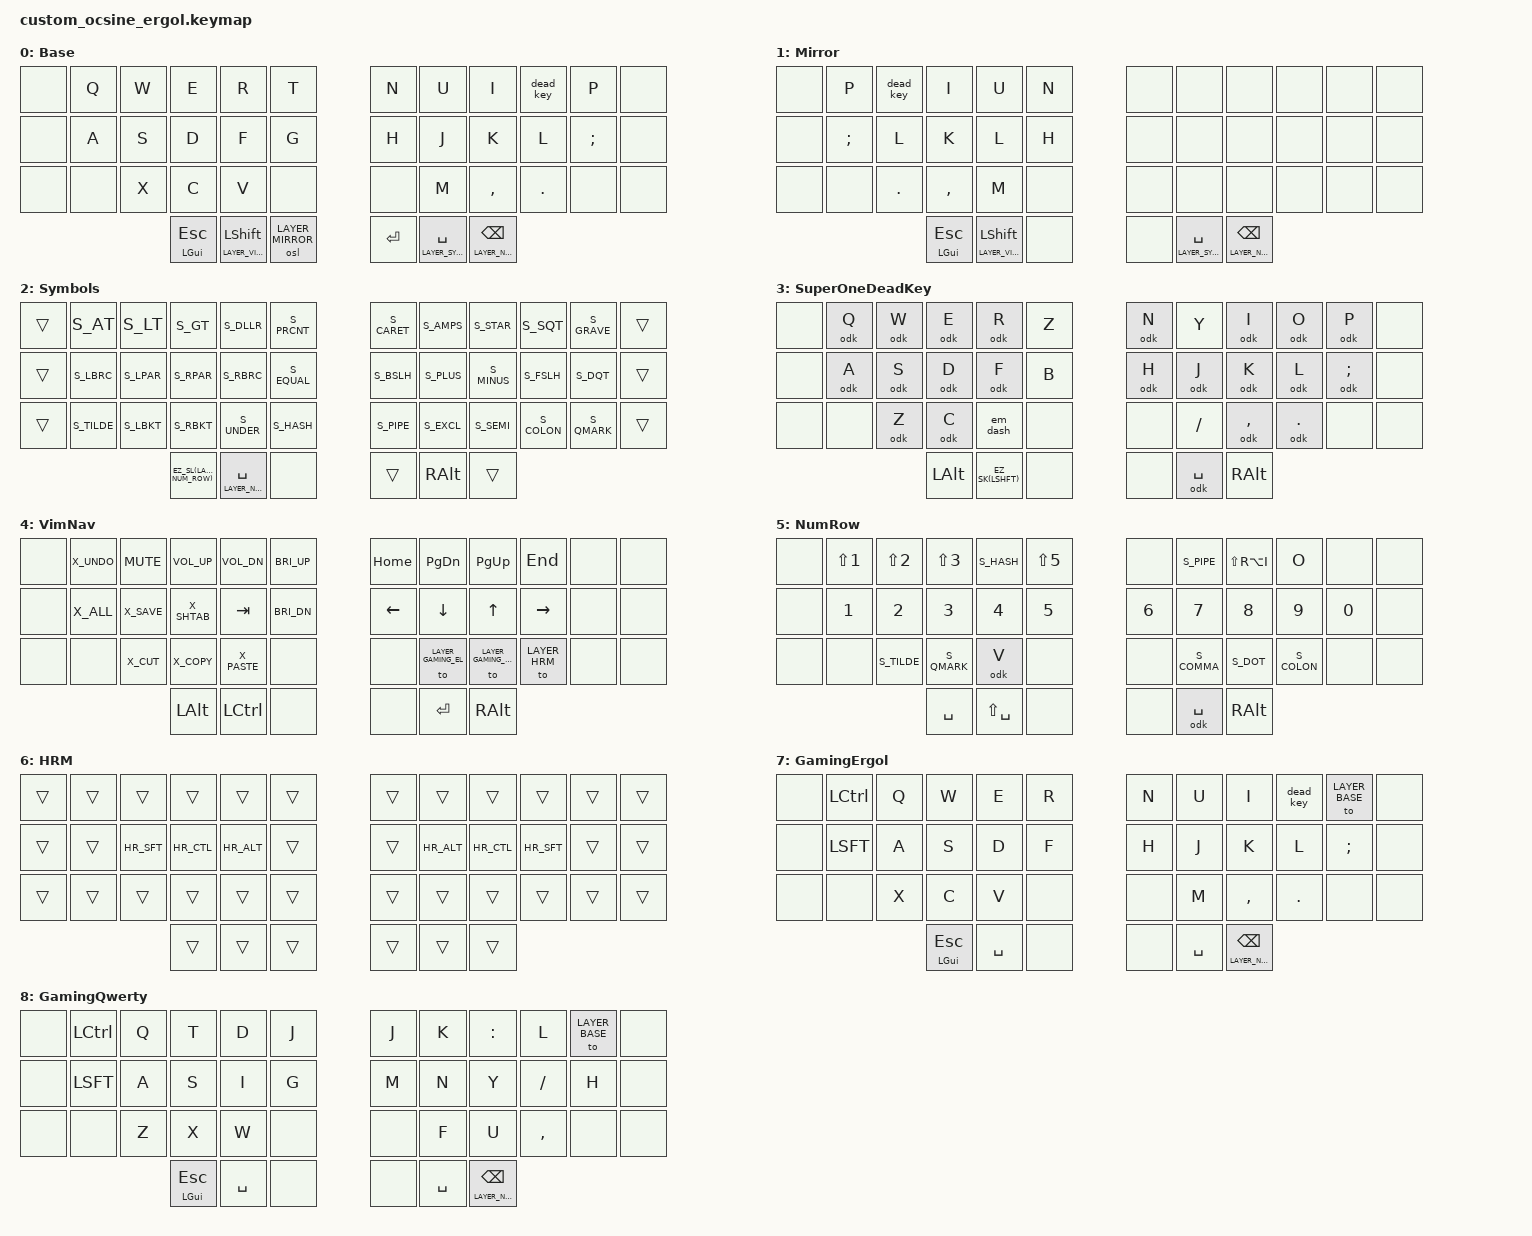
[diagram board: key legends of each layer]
#include <behaviors.dtsi>
#include <dt-bindings/zmk/keys.h>

#define TAPPING_TERM 175
#include "hold_taps.dtsi"

#define KB_LAYOUT_ERGOL
#include "aliases.h"

/* &caps_word { */
/*   no-default-keys; */
/*   continue-list = <C O N DOT BACKSPACE>; */
/*   shift-list = < */
/*     Q  W  E  R  T     Y  U  I     P */
/*     A  S  D  F  G     H  J  K  L  SEMI */
/*     Z  X     V  B        M  COMMA FSLH */
/*   >; */
/* }; */

#undef  HRM_S
#undef  HRM_L
#define HRM_S   &hrm LSFT S
#define HRM_L   &hrm LSFT L

&hrm { tapping-term-ms = <250>; };
#define COMBO_TIMEOUT_MS 17
#define COMBO_LOCK_MS 125

#define LAYER_BASE      0
#define LAYER_MIRROR    1
#define LAYER_SYMBOLS   2
#define LAYER_ODK       3
#define LAYER_VIM_NAV   4
#define LAYER_NUM_ROW   5
#define LAYER_HRM       6
#define LAYER_GAMING_EL 7
#define LAYER_GAMING_QW 8

#define S_MULT &kp LS(RA(I))

#define X_BASE    &to LAYER_BASE
#define X_HRM     &to LAYER_HRM
#define X_GAME_EL &to LAYER_GAMING_EL
#define X_GAME_QW &to LAYER_GAMING_QW

#define X_MUTE  &kp C_MUTE
#define X_VOLUP &kp C_VOL_UP
#define X_VOLDN &kp C_VOL_DN
#define X_BRIUP &kp C_BRI_UP
#define X_BRIDN &kp C_BRI_DN

/ {
  behaviors {
    hrt: hom_row_mods_transparent {
      compatible = "zmk,behavior-hold-tap";
      #binding-cells = <2>;
      tapping-term-ms = <250>;
      quick-tap-ms = <QUICK_TAP>;
      flavor = "tap-preferred";
      bindings = <&kp>, <&trans>;
    };

    ltsk: layer_tap_sticky_key {
      compatible = "zmk,behavior-hold-tap";
      #binding-cells = <2>;
      tapping-term-ms = <TAPPING_TERM>;
      flavor = "tap-preferred";
      bindings = <&mo>, <&osm>;
    };

    dead_key: dead_key {
      compatible = "zmk,behavior-mod-morph";
      #binding-cells = <0>;
      bindings = <&bsl LAYER_ODK LAYER_ODK>, <&kp O>;
      mods = <(MOD_LSFT|MOD_RSFT|MOD_RALT|MOD_LGUI)>;
      keep-mods = <(MOD_LSFT|MOD_RSFT|MOD_RALT|MOD_LGUI|MOD_LCTL)>;
    };

    /* // Macro to tap Ergo‑L’s ODK before the specified key */
    /* odk: one_dead_key_macro { */
    /*   compatible = "zmk,behavior-dead-key"; */
    /*   #binding-cells = <1>; */
    /*   dead-keycode = <O>; */
    /* }; */

    // Macro to tap Ergo‑L’s ODK before the specified key
    odk: one_dead_key_macro {
      compatible = "zmk,behavior-macro-one-param";
      #binding-cells = <1>;
      tap-ms = <0>;
      wait-ms = <0>;
      bindings
        = <&macro_tap &kp O>
        , <&macro_param_1to1>
        , <&macro_tap &kp MACRO_PLACEHOLDER>
        ;
    };

    em_dash: em_dash {
      compatible = "zmk,behavior-mod-morph";
      #binding-cells = <0>;
      bindings = <&odk V>, <&odk B>;
      mods = <(MOD_LSFT|MOD_RSFT)>;
    };

    /* macro_plus_to_zero: macro_plus_to_zero { */
    /*   compatible = "zmk,behavior-macro"; */
    /*   #binding-cells = <0>; */
    /*   tap-ms = <0>; */
    /*   wait-ms = <0>; */
    /*   bindings */
    /*     = <&macro_tap &kp BACKSPACE> */
    /*     , <&macro_tap &kp N0> */
    /*     ; */
    /* }; */
    /**/
    /* plus: magic_plus { */
    /*   compatible = "zmk,behavior-flow-key"; */
    /*   #binding-cells = <0>; */
    /*   timeout-ms = <QUICK_TAP>; */
    /*   bindings */
    /*     = <S_PLUS> */
    /*     , <S_MINUS &macro_plus_to_zero> */
    /*     ; */
    /* }; */
    /**/
    /* macro_minus_to_one: macro_minus_to_one { */
    /*   compatible = "zmk,behavior-macro"; */
    /*   #binding-cells = <0>; */
    /*   tap-ms = <0>; */
    /*   wait-ms = <0>; */
    /*   bindings */
    /*     = <&macro_tap &kp BACKSPACE> */
    /*     , <&macro_tap &kp N1> */
    /*     ; */
    /* }; */
    /**/
    /* minus: magic_minus { */
    /*   compatible = "zmk,behavior-flow-key"; */
    /*   #binding-cells = <0>; */
    /*   timeout-ms = <QUICK_TAP>; */
    /*   bindings */
    /*     = <S_MINUS> */
    /*     , <S_PLUS &macro_minus_to_one> */
    /*     ; */
    /* }; */
    /**/
    /* macro_slash_to_minus_one: macro_slash_to_minus_one { */
    /*   compatible = "zmk,behavior-macro"; */
    /*   #binding-cells = <0>; */
    /*   tap-ms = <0>; */
    /*   wait-ms = <0>; */
    /*   bindings */
    /*     = <&macro_tap &kp BACKSPACE> */
    /*     , <&macro_tap S_MINUS> */
    /*     , <&macro_tap &kp N1> */
    /*     ; */
    /* }; */
    /**/
    /* slash: magic_slash { */
    /*   compatible = "zmk,behavior-flow-key"; */
    /*   #binding-cells = <0>; */
    /*   timeout-ms = <QUICK_TAP>; */
    /*   bindings */
    /*     = <S_FSLH> */
    /*     , <S_PLUS &macro_slash_to_minus_one> */
    /*     ; */
    /* }; */
  };

  combos {
    compatible= "zmk,combos";

    #define HOME_ROW 12
    #define BOT_ROW  24

    #define LRING   2
    #define LMIDDLE 3
    #define LINDEX  4
    #define RINDEX  7
    #define RMIDDLE 8
    #define RRING   9

    compose_sd {
      key-positions = <(HOME_ROW + LRING) (HOME_ROW + LMIDDLE)>;
      bindings = <&kp NUBS>;
      timeout-ms = <COMBO_TIMEOUT_MS>;
      require-prior-idle-ms = <COMBO_LOCK_MS>;
      layers = <LAYER_BASE>;
    };

    /* enter_df { */
    /*   key-positions = <(HOME_ROW + LMIDDLE) (HOME_ROW + LINDEX)>; */
    /*   bindings = <&kp ENTER>; */
    /*   timeout-ms = <COMBO_TIMEOUT_MS>; */
    /*   require-prior-idle-ms = <COMBO_LOCK_MS>; */
    /*   layers = <LAYER_BASE>; */
    /* }; */

    /* escape_kj { */
    /*   key-positions = <(HOME_ROW + RINDEX) (HOME_ROW + RMIDDLE)>; */
    /*   bindings = <&kp ESCAPE>; */
    /*   timeout-ms = <COMBO_TIMEOUT_MS>; */
    /*   require-prior-idle-ms = <COMBO_LOCK_MS>; */
    /*   layers = <LAYER_BASE>; */
    /* }; */

    delete_word_lk {
      key-positions = <(HOME_ROW + RMIDDLE) (HOME_ROW + RRING)>;
      bindings = <&kp LC(BSPC)>;
      timeout-ms = <COMBO_TIMEOUT_MS>;
      require-prior-idle-ms = <COMBO_LOCK_MS>;
      layers = <LAYER_BASE>;
    };

    caps_word_m_comma {
      key-positions = <(BOT_ROW + RINDEX) (BOT_ROW + RMIDDLE)>;
      bindings = <&caps_word>;
      /* bindings = <&kp CAPSLOCK>; */
      timeout-ms = <COMBO_TIMEOUT_MS>;
      require-prior-idle-ms = <COMBO_LOCK_MS>;
      layers = <LAYER_BASE>;
    };
  };

  conditional_layers {
    compatible = "zmk,conditional-layers";
    enable_hrms {
      if-layers  = <LAYER_BASE>;
      then-layer = <LAYER_HRM>;
    };
  };

  keymap {
    compatible = "zmk,keymap";

    default_layer {
      display-name = "Base";
      bindings = <
        &none &kp Q &kp W &kp E &kp R &kp T      &kp N &kp U &kp I     &dead_key &kp P    &none
        &none &kp A &kp S &kp D &kp F &kp G      &kp H &kp J &kp K     &kp L     &kp SEMI &none
        &none &none &kp X &kp C &kp V &none      &none &kp M &kp COMMA &kp DOT   &none    &none
     &hrm LGUI ESCAPE  &ltsk LAYER_VIM_NAV LSHFT  &osl LAYER_MIRROR      &kp ENTER  &lt LAYER_SYMBOLS SPACE  &lt LAYER_NUM_ROW BSPC
      >;
    };

    mirror_layer {
      display-name = "Mirror";
      bindings = <
        &none &kp P    &dead_key &kp I     &kp U &kp N      &none &none &none &none &none &none
        &none &kp SEMI &kp L     &kp K     &kp L &kp H      &none &none &none &none &none &none
        &none &none    &kp DOT   &kp COMMA &kp M &none      &none &none &none &none &none &none
        &hrm LGUI ESCAPE  &ltsk LAYER_VIM_NAV LSHFT  &none      &none  &lt LAYER_SYMBOLS SPACE  &lt LAYER_NUM_ROW BSPC
      >;
    };

    symbols_layer {
      display-name = "Symbols";
      bindings = <
        &trans  S_AT    S_LT    S_GT    S_DLLR  S_PRCNT       S_CARET S_AMPS  S_STAR  S_SQT   S_GRAVE  &trans
        &trans  S_LBRC  S_LPAR  S_RPAR  S_RBRC  S_EQUAL       S_BSLH  S_PLUS  S_MINUS S_FSLH  S_DQT   &trans
        &trans  S_TILDE S_LBKT  S_RBKT  S_UNDER S_HASH        S_PIPE  S_EXCL  S_SEMI  S_COLON S_QMARK  &trans
        &EZ_SL(LAYER_NUM_ROW)  &lt LAYER_NUM_ROW SPACE  &none     &trans  &kp RALT  &trans
      >;
    };

    super_odk {
      display-name = "SuperOneDeadKey";
      bindings = <
        &none &odk Q &odk W &odk E &odk R   &kp Z     &odk N &kp Y    &odk I     &odk O   &odk P    &none
        &none &odk A &odk S &odk D &odk F   &kp B     &odk H &odk J   &odk K     &odk L   &odk SEMI &none
        &none &none  &odk Z &odk C &em_dash &none     &none  &kp FSLH &odk COMMA &odk DOT &none     &none
                   &kp LALT  &EZ_SK(LSHFT)  &none     &none  &odk SPACE  &kp RALT
      >;
    };

    vim_nav {
      display-name = "VimNav";
      bindings = <
        &none X_UNDO X_MUTE X_VOLUP X_VOLDN X_BRIUP     &kp HOME &kp PG_DN &kp PG_UP &kp END   &none &none
        &none X_ALL  X_SAVE X_SHTAB &kp TAB X_BRIDN     &kp LEFT &kp DOWN  &kp UP    &kp RIGHT &none &none
        &none &none  X_CUT  X_COPY  X_PASTE &none       &none    X_GAME_EL X_GAME_QW X_HRM     &none &none
                        &kp LALT  &kp LCTL  &none       &none  &kp ENTER  &kp RALT
      >;
    };

    num_row {
      display-name = "NumRow";
      bindings = <
        &none &kp LS(N1) &kp LS(N2) &kp LS(N3) S_HASH &kp LS(N5)     &none  S_PIPE   S_MULT &kp O   &none  &none
        &none &kp N1     &kp N2     &kp N3     &kp N4 &kp N5         &kp N6 &kp N7   &kp N8 &kp N9  &kp N0 &none
        &none &none      S_TILDE    S_QMARK    &odk V &none          &none  S_COMMA  S_DOT  S_COLON &none  &none
                             &kp SPACE  &kp LS(SPACE)  &none       &none  &odk SPACE  &kp RALT
      >;
    };

    #define HR_SFT &hrt LSFT 0
    #define HR_CTL &hrt LCTL 0
    #define HR_ALT &hrt LALT 0

    home_row_mods {
      display-name = "HRM";
      bindings = <
        &trans &trans &trans &trans &trans &trans     &trans &trans &trans &trans &trans &trans
        &trans &trans HR_SFT HR_CTL HR_ALT &trans     &trans HR_ALT HR_CTL HR_SFT &trans &trans
        &trans &trans &trans &trans &trans &trans     &trans &trans &trans &trans &trans &trans
                             &trans &trans &trans     &trans &trans &trans
      >;
    };

    #undef HR_SFT
    #undef HR_CTL
    #undef HR_ALT

    gaming_ergol {
      display-name = "GamingErgol";
      bindings = <
        &none &kp LCTL &kp Q &kp W &kp E &kp R      &kp N &kp U &kp I     &dead_key X_BASE   &none
        &none &kp LSFT &kp A &kp S &kp D &kp F      &kp H &kp J &kp K     &kp L     &kp SEMI &none
        &none &none    &kp X &kp C &kp V &none      &none &kp M &kp COMMA &kp DOT   &none    &none
            &hrm LGUI ESCAPE  &kp SPACE  &none      &none  &kp SPACE  &lt LAYER_NUM_ROW BSPC
      >;
    };

    gaming_qwerty {
      display-name = "GamingQwerty";
      bindings = <
        &none &kp LCTL &kp Q &kp T &kp D &kp J      &kp J &kp K &kp COLON &kp L     X_BASE &none
        &none &kp LSFT &kp A &kp S &kp I &kp G      &kp M &kp N &kp Y     &kp FSLH  &kp H  &none
        &none &none    &kp Z &kp X &kp W &none      &none &kp F &kp U     &kp COMMA &none  &none
            &hrm LGUI ESCAPE  &kp SPACE  &none      &none  &kp SPACE  &lt LAYER_NUM_ROW BSPC
      >;
    };

  };
};
